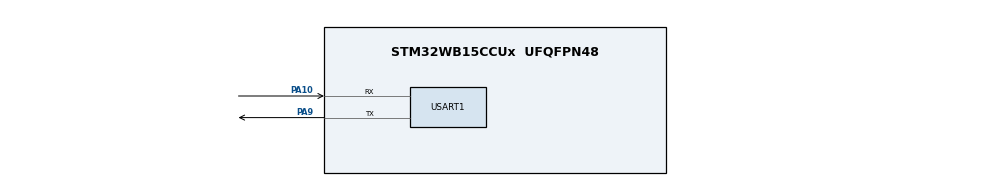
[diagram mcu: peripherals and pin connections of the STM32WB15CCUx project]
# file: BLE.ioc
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Mcu.Family=STM32WB
Mcu.Name=STM32WB15CCUx
Mcu.Package=UFQFPN48
NUCLEO-WB15CC.BUTTON=1
NUCLEO-WB15CC.BUTTON2=1
NUCLEO-WB15CC.BUTTON3=1
NUCLEO-WB15CC.LD1=true
NUCLEO-WB15CC.LD2=true
NUCLEO-WB15CC.LD3=true
NUCLEO-WB15CC.VCP=false
NVIC.HSEM_IRQn=true\:0\:0\:false\:false\:true\:false\:true\:true
NVIC.IPCC_C1_RX_IRQn=true\:0\:0\:false\:false\:true\:true\:true\:true
NVIC.IPCC_C1_TX_IRQn=true\:0\:0\:false\:false\:true\:true\:true\:true
NVIC.PriorityGroup=NVIC_PRIORITYGROUP_4
NVIC.RTC_WKUP_IRQn=true\:0\:0\:false\:false\:true\:true\:true\:true
OSC_IN.GPIO_Label=RCC_OSC_IN
OSC_IN.Mode=HSE-External-Oscillator
OSC_IN.Signal=RCC_OSC_IN
OSC_OUT.GPIO_Label=RCC_OSC_OUT
OSC_OUT.Mode=HSE-External-Oscillator
OSC_OUT.Signal=RCC_OSC_OUT
PA10.Mode=Asynchronous
PA10.Signal=USART1_RX
PA13.GPIO_Label=JTMS
PA13.Mode=Trace_Asynchronous_SW
PA13.Signal=SYS_JTMS-SWDIO
PA14.GPIO_Label=JTCK
PA14.Mode=Trace_Asynchronous_SW
PA14.Signal=SYS_JTCK-SWCLK
PA9.Mode=Asynchronous
PA9.Signal=USART1_TX
PB3.GPIO_Label=JTDO
PB3.Mode=Trace_Asynchronous_SW
PB3.Signal=SYS_JTDO-SWO
PC14-OSC32_IN.GPIO_Label=RCC_OSC32_IN
PC14-OSC32_IN.Mode=LSE-External-Oscillator
PC14-OSC32_IN.Signal=RCC_OSC32_IN
PC15-OSC32_OUT.GPIO_Label=RCC_OSC32_OUT
PC15-OSC32_OUT.Mode=LSE-External-Oscillator
PC15-OSC32_OUT.Signal=RCC_OSC32_OUT
ProjectManager.HeapSize=0x200
ProjectManager.StackSize=0x400
ProjectManager.TargetToolchain=STM32CubeIDE
RCC.AHBFreq_Value=32000000
RCC.APB1Freq_Value=32000000
RCC.APB1TimFreq_Value=32000000
RCC.APB2Freq_Value=32000000
RCC.APB2TimFreq_Value=32000000
RCC.APB3Freq_Value=16000000
RCC.CortexFreq_Value=32000000
RCC.HCLKFreq_Value=32000000
RCC.HSE_VALUE=32000000
RCC.HSI_VALUE=16000000
RCC.LSE_Drive_Capability=RCC_LSEDRIVE_LOW
RCC.MSIClockRange=RCC_MSIRANGE_10
RCC.SYSCLKFreq_VALUE=32000000
RCC.VCOOutputFreq_Value=256000000
RF1.Mode=RF1_Activate
RF1.Signal=RF_RF1
STM32_WPAN.CFG_LSCLK_LSE=0
STM32_WPAN.CUSTOM_P2P_SERVER=Disabled
STM32_WPAN.CUSTOM_TEMPLATE=Enabled
STM32_WPAN.INCLUDE_AD_TYPE_COMPLETE_LOCAL_NAME=1
STM32_WPAN.NUMBER_OF_SERVICES=1
STM32_WPAN.SERVICE1_CHAR1_GATT_NOTIFY_READ_REQ_AND_WAIT_FOR_APPL_RESP=\ 
STM32_WPAN.SERVICE1_CHAR1_GATT_NOTIFY_WRITE_REQ_AND_WAIT_FOR_APPL_RESP=\ 
STM32_WPAN.SERVICE1_CHAR1_LENGTH_CHARACTERISTIC=CHAR_VALUE_LEN_VARIABLE
STM32_WPAN.SERVICE1_CHAR1_LONG_NAME=charWrite
STM32_WPAN.SERVICE1_CHAR1_PROP_WRITE=CHAR_PROP_WRITE
STM32_WPAN.SERVICE1_CHAR1_SHORT_NAME=charWrite
STM32_WPAN.SERVICE1_CHAR1_VALUE_LENGTH=512
STM32_WPAN.SERVICE1_LONG_NAME=myService
STM32_WPAN.SERVICE1_SHORT_NAME=myService
USART1.VirtualMode-Asynchronous=VM_ASYNC
VP_HSEM_VS_HSEM.Mode=HSEM_Activate
VP_IPCC_VS_IPCC.Mode=IPCC_Activate
VP_MEMORYMAP_VS_MEMORYMAP.Mode=CurAppReg
VP_NUCLEO-WB15CC_VS_BSP_COMMON.Mode=COMMON
VP_RTC_VS_RTC_Activate.Mode=RTC_Enabled
VP_RTC_VS_RTC_WakeUp_intern.Mode=WakeUp
VP_SEQUENCER_VS_SEQUENCER.Mode=SEQUENCER_Enabled
VP_STM32_WPAN_VS_BLE_HOST.Mode=STM32_WPAN_Enabled
VP_TINY_LPM_VS_TINY_LPM.Mode=TINY_LPM_Enabled
board=NUCLEO-WB15CC

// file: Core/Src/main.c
/* USER CODE BEGIN Header */
/**
 ******************************************************************************
 * @file           : main.c
 * @brief          : Main program body
 ******************************************************************************
 * @attention
 *
 * Copyright (c) 2025 STMicroelectronics.
 * All rights reserved.
 *
 * This software is licensed under terms that can be found in the LICENSE file
 * in the root directory of this software component.
 * If no LICENSE file comes with this software, it is provided AS-IS.
 *
 ******************************************************************************
 */
/* USER CODE END Header */
#include "main.h"
#include "ipcc.h"
#include "rf.h"
#include "rtc.h"
#include "usart.h"
#include "gpio.h"

/* USER CODE BEGIN Includes */
#include <stdio.h>
/* USER CODE END Includes */

void SystemClock_Config(void);
void PeriphCommonClock_Config(void);

/* USER CODE BEGIN 0 */
int __io_putchar(int chr){
	HAL_UART_Transmit(&huart1, (uint8_t*) &chr, 1, HAL_MAX_DELAY);
	return chr;
}
/* USER CODE END 0 */

int main(void)
{

  /* MCU Configuration--------------------------------------------------------*/

  /* Reset of all peripherals, Initializes the Flash interface and the Systick. */
  HAL_Init();
  /* Config code for STM32_WPAN (HSE Tuning must be done before system clock configuration) */
  MX_APPE_Config();

  /* Configure the system clock */
  SystemClock_Config();

  /* Configure the peripherals common clocks */
  PeriphCommonClock_Config();

  /* IPCC initialisation */
  MX_IPCC_Init();

  /* Initialize all configured peripherals */
  MX_GPIO_Init();
  MX_RTC_Init();
  MX_USART1_UART_Init();
  MX_RF_Init();
  /* USER CODE BEGIN 2 */
  printf("\r\n==== BLE TEST ====\r\n");
  /* USER CODE END 2 */

  /* Init code for STM32_WPAN */
  MX_APPE_Init();

  /* Initialize leds */
  BSP_LED_Init(LED_BLUE);
  BSP_LED_Init(LED_GREEN);
  BSP_LED_Init(LED_RED);

  /* Initialize USER push-button, will be used to trigger an interrupt each time it's pressed.*/
  BSP_PB_Init(BUTTON_SW1, BUTTON_MODE_EXTI);
  BSP_PB_Init(BUTTON_SW2, BUTTON_MODE_EXTI);
  BSP_PB_Init(BUTTON_SW3, BUTTON_MODE_EXTI);

  /* Infinite loop */
	while (1)
	{
    MX_APPE_Process();

	}
}

void SystemClock_Config(void)
{
  RCC_OscInitTypeDef RCC_OscInitStruct = {0};
  RCC_ClkInitTypeDef RCC_ClkInitStruct = {0};

  /** Configure LSE Drive Capability
  */
  HAL_PWR_EnableBkUpAccess();
  __HAL_RCC_LSEDRIVE_CONFIG(RCC_LSEDRIVE_LOW);

  /** Initializes the RCC Oscillators according to the specified parameters
  * in the RCC_OscInitTypeDef structure.
  */
  RCC_OscInitStruct.OscillatorType = RCC_OSCILLATORTYPE_HSI|RCC_OSCILLATORTYPE_LSI1
                              |RCC_OSCILLATORTYPE_HSE|RCC_OSCILLATORTYPE_LSE
                              |RCC_OSCILLATORTYPE_MSI;
  RCC_OscInitStruct.HSEState = RCC_HSE_ON;
  RCC_OscInitStruct.LSEState = RCC_LSE_ON;
  RCC_OscInitStruct.HSIState = RCC_HSI_ON;
  RCC_OscInitStruct.MSIState = RCC_MSI_ON;
  RCC_OscInitStruct.HSICalibrationValue = RCC_HSICALIBRATION_DEFAULT;
  RCC_OscInitStruct.MSICalibrationValue = RCC_MSICALIBRATION_DEFAULT;
  RCC_OscInitStruct.MSIClockRange = RCC_MSIRANGE_10;
  RCC_OscInitStruct.LSIState = RCC_LSI_ON;
  RCC_OscInitStruct.PLL.PLLState = RCC_PLL_NONE;
  if (HAL_RCC_OscConfig(&RCC_OscInitStruct) != HAL_OK)
  {
    Error_Handler();
  }

  /** Configure the SYSCLKSource, HCLK, PCLK1 and PCLK2 clocks dividers
  */
  RCC_ClkInitStruct.ClockType = RCC_CLOCKTYPE_HCLK4|RCC_CLOCKTYPE_HCLK2
                              |RCC_CLOCKTYPE_HCLK|RCC_CLOCKTYPE_SYSCLK
                              |RCC_CLOCKTYPE_PCLK1|RCC_CLOCKTYPE_PCLK2;
  RCC_ClkInitStruct.SYSCLKSource = RCC_SYSCLKSOURCE_MSI;
  RCC_ClkInitStruct.AHBCLKDivider = RCC_SYSCLK_DIV1;
  RCC_ClkInitStruct.APB1CLKDivider = RCC_HCLK_DIV1;
  RCC_ClkInitStruct.APB2CLKDivider = RCC_HCLK_DIV1;
  RCC_ClkInitStruct.AHBCLK2Divider = RCC_SYSCLK_DIV1;
  RCC_ClkInitStruct.AHBCLK4Divider = RCC_SYSCLK_DIV1;

  if (HAL_RCC_ClockConfig(&RCC_ClkInitStruct, FLASH_LATENCY_1) != HAL_OK)
  {
    Error_Handler();
  }

  /** Enable MSI Auto calibration
  */
  HAL_RCCEx_EnableMSIPLLMode();
}

void PeriphCommonClock_Config(void)
{
  RCC_PeriphCLKInitTypeDef PeriphClkInitStruct = {0};

  /** Initializes the peripherals clock
  */
  PeriphClkInitStruct.PeriphClockSelection = RCC_PERIPHCLK_SMPS|RCC_PERIPHCLK_RFWAKEUP;
  PeriphClkInitStruct.RFWakeUpClockSelection = RCC_RFWKPCLKSOURCE_LSI;
  PeriphClkInitStruct.SmpsClockSelection = RCC_SMPSCLKSOURCE_HSI;
  PeriphClkInitStruct.SmpsDivSelection = RCC_SMPSCLKDIV_RANGE1;

  if (HAL_RCCEx_PeriphCLKConfig(&PeriphClkInitStruct) != HAL_OK)
  {
    Error_Handler();
  }
}

void Error_Handler(void)
{
	__disable_irq();
	while (1)
	{
	}
}
